AUTOSAR XML (schema 00052)
package /apd/LogAndTraceInterface
  log and trace interface TraceIntegrationTest2
    namespaces:
      symbol props apd
      symbol props wgres
package /apd/AdaptiveApplicationSwComponentTypes
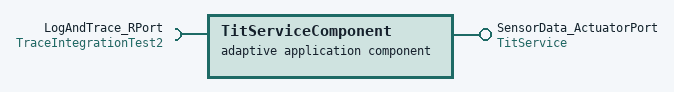
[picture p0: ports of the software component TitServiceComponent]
  adaptive application sw component type TitServiceComponent
    provide port SensorData_ActuatorPort: provided-interface=TitService
    require port LogAndTrace_RPort: required-interface=TraceIntegrationTest2
package /apd/Executables
  executable RES_TraceIntegrationTest2: category=APPLICATION_LEVEL, minimum-timer-granularity=1000, trace-switch-configuration{trace-message=Test1Msg, trace-switch=TRACE-SWITCH-LOG}
    root sw component prototype RES_TraceIntegrationTest2: application-type=TitServiceComponent
